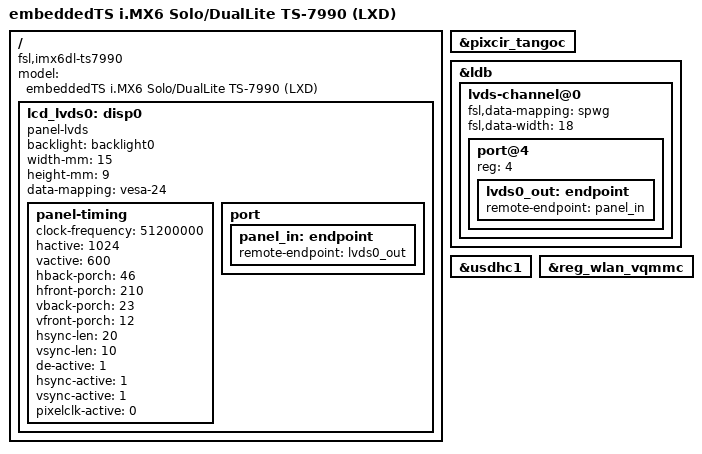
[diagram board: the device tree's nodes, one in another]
// SPDX-License-Identifier: GPL-2.0 OR X11
/*
 * Copyright 2017-2022 Technologic Systems, Inc. dba embeddedTS
 */

/dts-v1/;
#include "imx6dl.dtsi"
#include "imx6qdl-ts7990.dtsi"

/ {
	model = "embeddedTS i.MX6 Solo/DualLite TS-7990 (LXD)";
	compatible = "fsl,imx6dl-ts7990", "fsl,imx6dl";

	lcd_lvds0: disp0 {
		compatible = "panel-lvds";
		backlight = <&backlight0>;
		width-mm = <15>;
		height-mm = <9>;
		data-mapping = "vesa-24";

		panel-timing {
			clock-frequency = <51200000>;
			hactive = <1024>;
			vactive = <600>;
			hback-porch = <46>;
			hfront-porch = <210>;
			vback-porch = <23>;
			vfront-porch = <12>;
			hsync-len = <20>;
			vsync-len = <10>;
			de-active = <1>;
			hsync-active = <1>;
			vsync-active = <1>;
			pixelclk-active = <0>;
		};

		port {
			panel_in: endpoint {
				remote-endpoint = <&lvds0_out>;
			};
		};
	};
};

&pixcir_tangoc {
	status = "okay";
};

&ldb {
	status = "okay";

	lvds-channel@0 {
		fsl,data-mapping = "spwg";
		fsl,data-width = <18>;

		status = "okay";

		port@4 {
			reg = <4>;

			lvds0_out: endpoint {
				remote-endpoint = <&panel_in>;
			};
		};
	};
};

&usdhc1 {
	status = "okay";
};

&reg_wlan_vqmmc {
	status = "okay";
};
